NS_ :

BS_:

BU_:
	NEO
	MCU
	GTW
	EPAS
	DI
	ESP
	SBW
	STW
	APP
	DAS
	XXX

VAL_TABLE_ StW_AnglHP_Spd 16383 "SNA" ;
VAL_TABLE_ DI_aebFaultReason 15 "DI_AEB_FAULT_DAS_REQ_DI_UNAVAIL" 14 "DI_AEB_FAULT_ACCEL_REQ_INVALID" 13 "DI_AEB_FAULT_MIN_TIME_BTWN_EVENTS" 12 "DI_AEB_FAULT_ESP_MIA" 11 "DI_AEB_FAULT_ESP_FAULT" 10 "DI_AEB_FAULT_EPB_NOT_PARKED" 9 "DI_AEB_FAULT_ACCEL_OUT_OF_BOUNDS" 8 "DI_AEB_FAULT_PM_REQUEST" 7 "DI_AEB_FAULT_VEL_EST_ABNORMAL" 6 "DI_AEB_FAULT_DAS_SNA" 5 "DI_AEB_FAULT_DAS_CONTROL_MIA" 4 "DI_AEB_FAULT_SPEED_DELTA" 3 "DI_AEB_FAULT_EBR_FAULT" 2 "DI_AEB_FAULT_PM_MIA" 1 "DI_AEB_FAULT_EPB_MIA" 0 "DI_AEB_FAULT_NONE" ;
VAL_TABLE_ DI_aebLockState 3 "AEB_LOCK_STATE_SNA" 2 "AEB_LOCK_STATE_UNUSED" 1 "AEB_LOCK_STATE_UNLOCKED" 0 "AEB_LOCK_STATE_LOCKED" ;
VAL_TABLE_ DI_aebSmState 7 "DI_AEB_STATE_FAULT" 6 "DI_AEB_STATE_EXIT" 5 "DI_AEB_STATE_STANDSTILL" 4 "DI_AEB_STATE_STOPPING" 3 "DI_AEB_STATE_ENABLE" 2 "DI_AEB_STATE_ENABLE_INIT" 1 "DI_AEB_STATE_STANDBY" 0 "DI_AEB_STATE_UNAVAILABLE" ;
VAL_TABLE_ DI_aebState 7 "AEB_CAN_STATE_SNA" 4 "AEB_CAN_STATE_FAULT" 3 "AEB_CAN_STATE_STANDSTILL" 2 "AEB_CAN_STATE_ENABLED" 1 "AEB_CAN_STATE_STANDBY" 0 "AEB_CAN_STATE_UNAVAILABLE" ;
VAL_TABLE_ DI_epbInterfaceReady 1 "EPB_INTERFACE_READY" 0 "EPB_INTERFACE_NOT_READY" ;
VAL_TABLE_ DI_gear 7 "DI_GEAR_SNA" 4 "DI_GEAR_D" 3 "DI_GEAR_N" 2 "DI_GEAR_R" 1 "DI_GEAR_P" 0 "DI_GEAR_INVALID" ;
VAL_TABLE_ DI_gpoReason 8 "DI_GPO_NUMREASONS" 7 "DI_GPO_CAPACITOR_OVERTEMP" 6 "DI_GPO_NOT_ENOUGH_12V" 5 "DI_GPO_NO_BATTERY_POWER" 4 "DI_GPO_AMBIENT_OVERTEMP" 3 "DI_GPO_FLUID_DELTAT" 2 "DI_GPO_STATOR_OVERTEMP" 1 "DI_GPO_HEATSINK_OVERTEMP" 0 "DI_GPO_OUTLET_OVERTEMP" ;
VAL_TABLE_ DI_immobilizerCondition 1 "DI_IMM_CONDITION_LEARNED" 0 "DI_IMM_CONDITION_VIRGIN_SNA" ;
VAL_TABLE_ DI_immobilizerState 7 "DI_IMM_STATE_FAULT" 6 "DI_IMM_STATE_FAULTRETRY" 5 "DI_IMM_STATE_RESET" 4 "DI_IMM_STATE_LEARN" 3 "DI_IMM_STATE_DISARMED" 2 "DI_IMM_STATE_AUTHENTICATING" 1 "DI_IMM_STATE_REQUEST" 0 "DI_IMM_STATE_INIT_SNA" ;
VAL_TABLE_ DI_limpReason 24 "DI_LIMP_NUMREASONS" 23 "DI_LIMP_CAPACITOR_OVERTEMP" 22 "DI_LIMP_GTW_MIA" 21 "DI_LIMP_TRQCMD_VALIDITY_UNKNOWN" 20 "DI_LIMP_DI_MIA" 19 "DI_LIMP_CONFIG_MISMATCH" 18 "DI_LIMP_HEATSINK_TEMP" 17 "DI_LIMP_PMREQUEST" 16 "DI_LIMP_PMHEARTBEAT" 15 "DI_LIMP_TRQ_CROSS_CHECK" 14 "DI_LIMP_EXTERNAL_COMMAND" 13 "DI_LIMP_WRONG_CS_CALIBRATION" 12 "DI_LIMP_STATOR_TEMP" 11 "DI_LIMP_DELTAT_TOO_NEGATIVE" 10 "DI_LIMP_DELTAT_TOO_POSITIVE" 9 "DI_LIMP_AMBIENT_TEMP" 8 "DI_LIMP_OUTLET_TEMP" 7 "DI_LIMP_LOW_FLOW" 6 "DI_LIMP_BMS_MIA" 5 "DI_LIMP_12V_SUPPLY_UNDERVOLTAGE" 4 "DI_LIMP_NO_FLUID" 3 "DI_LIMP_NO_FUNC_HEATSINK_SENSOR" 2 "DI_LIMP_NO_FUNC_STATORT_SENSOR" 1 "DI_LIMP_BUSV_SENSOR_IRRATIONAL" 0 "DI_LIMP_PHASE_IMBALANCE" ;
VAL_TABLE_ DI_mode 2 "DI_MODE_DYNO" 1 "DI_MODE_DRIVE" 0 "DI_MODE_UNDEF" ;
VAL_TABLE_ DI_motorType 14 "DI_MOTOR_F2AE" 13 "DI_MOTOR_F2AD" 12 "DI_MOTOR_F2AC" 11 "DI_MOTOR_F2AB" 10 "DI_MOTOR_F1AC" 9 "DI_MOTOR_SSR1A" 8 "DI_MOTOR_F1A" 7 "DI_MOTOR_M7M6" 6 "DI_MOTOR_M8A" 5 "DI_MOTOR_M7M5" 4 "DI_MOTOR_M7M4" 3 "DI_MOTOR_M7M3" 2 "DI_MOTOR_ROADSTER_SPORT" 1 "DI_MOTOR_ROADSTER_BASE" 0 "DI_MOTOR_SNA" ;
VAL_TABLE_ DI_speedUnits 1 "DI_SPEED_KPH" 0 "DI_SPEED_MPH" ;
VAL_TABLE_ DI_state 4 "DI_STATE_ENABLE" 3 "DI_STATE_FAULT" 2 "DI_STATE_CLEAR_FAULT" 1 "DI_STATE_STANDBY" 0 "DI_STATE_PREAUTH" ;
VAL_TABLE_ DI_velocityEstimatorState 4 "VE_STATE_BACKUP_MOTOR" 3 "VE_STATE_BACKUP_WHEELS_B" 2 "VE_STATE_BACKUP_WHEELS_A" 1 "VE_STATE_WHEELS_NORMAL" 0 "VE_STATE_NOT_INITIALIZED" ;

BO_ 928 EPB_STATUS: 8 XXX
 SG_ EPB_BRAKE : 16|1@1+ (1,0) [0|3] "" XXX

BO_ 1104 SEATBELT_STATUS: 8 XXX
 SG_ DRIVER_SEAT_BELT_ONOFF : 21|1@0+ (1,0) [0|3] "" XXX

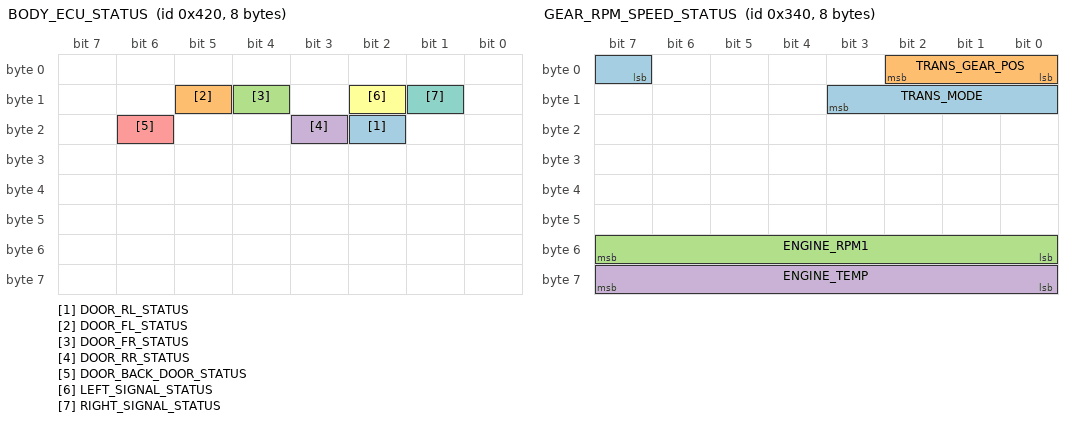
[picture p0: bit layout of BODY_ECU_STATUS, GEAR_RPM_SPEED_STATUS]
BO_ 1056 BODY_ECU_STATUS: 8 XXX
 SG_ DOOR_RL_STATUS : 18|1@0+ (1,0) [0|255] "" XXX
 SG_ DOOR_FL_STATUS : 13|1@0+ (1,0) [0|1] "" XXX
 SG_ DOOR_FR_STATUS : 12|1@0+ (1,0) [0|1] "" XXX
 SG_ DOOR_RR_STATUS : 19|1@0+ (1,0) [0|1] "" XXX
 SG_ DOOR_BACK_DOOR_STATUS : 22|1@0+ (1,0) [0|1] "" XXX
 SG_ LEFT_SIGNAL_STATUS : 10|1@0+ (1,0) [0|1] "" XXX
 SG_ RIGHT_SIGNAL_STATUS : 9|1@0+ (1,0) [0|1] "" XXX

BO_ 832 GEAR_RPM_SPEED_STATUS: 8 XXX
 SG_ TRANS_MODE : 7|5@1+ (1,0) [0|0] "" XXX
 SG_ TRANS_GEAR_POS : 2|3@0+ (1,0) [0|1] "" XXX
 SG_ ENGINE_RPM1 : 55|8@0+ (1,0) [0|255] "" XXX
 SG_ ENGINE_TEMP : 63|8@0+ (1,0) [0|255] "" XXX

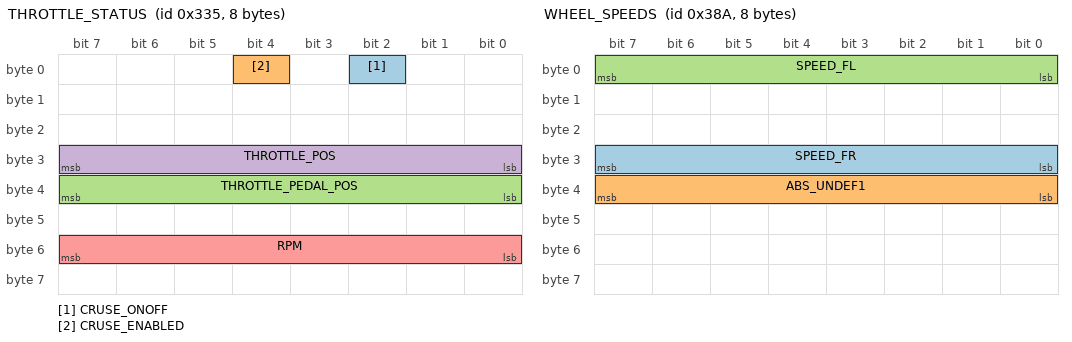
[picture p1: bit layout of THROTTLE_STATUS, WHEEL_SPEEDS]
BO_ 821 THROTTLE_STATUS: 8 XXX
 SG_ CRUSE_ONOFF : 2|1@0+ (1,0) [0|1] "on/off" XXX
 SG_ CRUSE_ENABLED : 4|1@0+ (1,0) [0|1] "" XXX
 SG_ THROTTLE_PEDAL_POS : 32|8@1+ (1,0) [0|255] "" XXX
 SG_ THROTTLE_POS : 24|8@1+ (1,0) [0|255] "" XXX
 SG_ RPM : 48|8@1- (1,0) [0|65535] "" XXX

BO_ 922 STEERING_ANGLE_STATUS: 8 XXX
 SG_ STEER_ANGLE_9000 : 7|16@0- (1,0) [0|65535] "" XXX

BO_ 906 WHEEL_SPEEDS: 8 XXX
 SG_ SPEED_FR : 24|8@1+ (1,0) [0|255] "" XXX
 SG_ ABS_UNDEF1 : 32|8@1+ (1,0) [0|255] "" XXX
 SG_ SPEED_FL : 0|8@1+ (1,0) [0|255] "" XXX

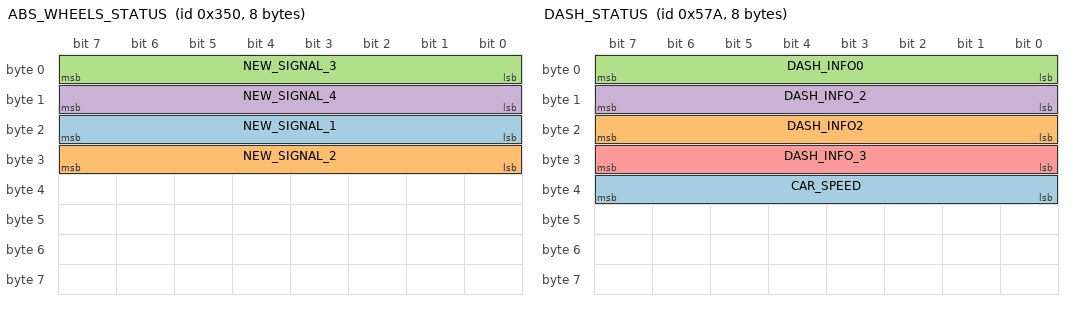
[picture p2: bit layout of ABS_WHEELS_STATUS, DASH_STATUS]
BO_ 848 ABS_WHEELS_STATUS: 8 XXX
 SG_ NEW_SIGNAL_1 : 23|8@0+ (1,0) [0|255] "" XXX
 SG_ NEW_SIGNAL_2 : 31|8@0+ (1,0) [0|255] "" XXX
 SG_ NEW_SIGNAL_3 : 7|8@0+ (1,0) [0|255] "" XXX
 SG_ NEW_SIGNAL_4 : 15|8@0+ (1,0) [0|255] "" XXX

BO_ 1402 DASH_STATUS: 8 XXX
 SG_ CAR_SPEED : 32|8@1+ (1,0) [0|255] "" XXX
 SG_ DASH_INFO2 : 16|8@1+ (1,0) [0|255] "" XXX
 SG_ DASH_INFO0 : 0|8@1+ (1,0) [0|255] "" XXX
 SG_ DASH_INFO_2 : 15|8@0+ (1,0) [0|255] "" XXX
 SG_ DASH_INFO_3 : 31|8@0+ (1,0) [0|255] "" XXX

BO_ 1306 _SPEEDX: 8 XXX
 SG_ DASH_CAR_SPEED : 7|9@0+ (1,0) [0|255] "" XXX

BO_ 1296 undefined: 8 XXX

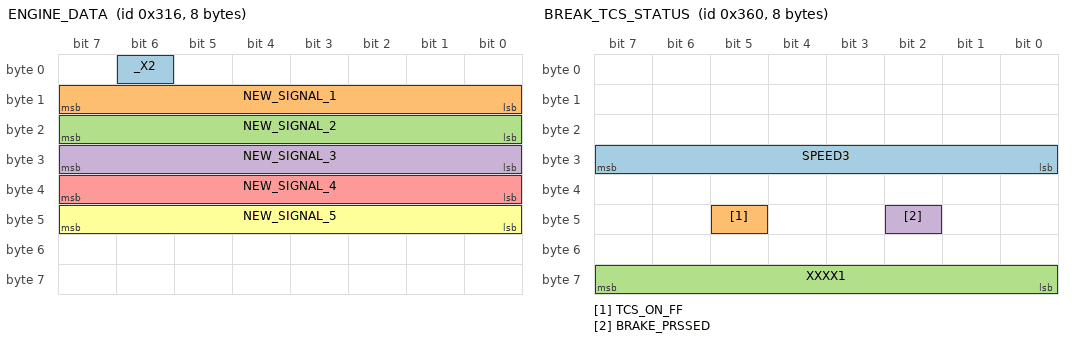
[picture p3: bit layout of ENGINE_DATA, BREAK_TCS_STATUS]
BO_ 790 ENGINE_DATA: 8 XXX
 SG_ _X2 : 6|1@0+ (1,0) [0|1] "" XXX
 SG_ NEW_SIGNAL_1 : 15|8@0+ (1,0) [0|255] "" XXX
 SG_ NEW_SIGNAL_2 : 23|8@0+ (1,0) [0|255] "" XXX
 SG_ NEW_SIGNAL_3 : 31|8@0+ (1,0) [0|255] "" XXX
 SG_ NEW_SIGNAL_4 : 39|8@0+ (1,0) [0|255] "" XXX
 SG_ NEW_SIGNAL_5 : 47|8@0+ (1,0) [0|255] "" XXX

BO_ 1313 undefined_2: 8 XXX

BO_ 1312 __trigger_every_range: 8 XXX
 SG_ __SIGNAL_every_interval : 4|1@0+ (1,0) [0|1] "" XXX

BO_ 896 undefined_3: 8 XXX
 SG_ NEW_SIGNAL_1 : 32|4@1+ (1,0) [0|15] "" XXX

BO_ 809 undefined_4: 8 XXX

BO_ 864 BREAK_TCS_STATUS: 8 XXX
 SG_ SPEED3 : 24|8@1+ (1,0) [0|255] "" XXX
 SG_ TCS_ON_FF : 45|1@0+ (1,0) [0|1] "" XXX
 SG_ XXXX1 : 63|8@0+ (1,0) [0|255] "" XXX
 SG_ BRAKE_PRSSED : 42|1@0+ (1,0) [0|1] "" XXX

BO_ 842 undefined_5: 8 XXX

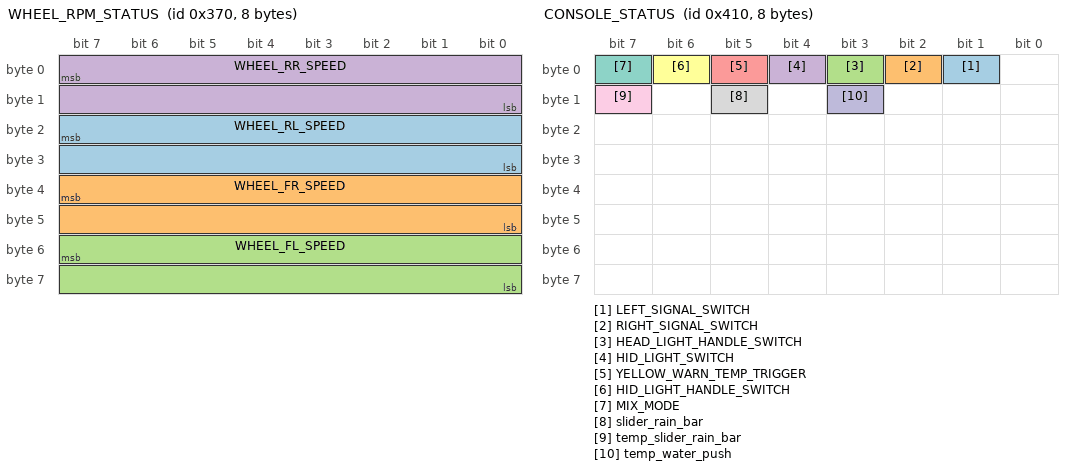
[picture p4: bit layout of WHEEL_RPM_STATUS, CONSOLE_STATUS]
BO_ 880 WHEEL_RPM_STATUS: 8 XXX
 SG_ WHEEL_RL_SPEED : 23|16@0+ (1,0) [0|255] "" XXX
 SG_ WHEEL_FR_SPEED : 39|16@0+ (1,0) [0|255] "" XXX
 SG_ WHEEL_FL_SPEED : 55|16@0+ (1,0) [0|255] "" XXX
 SG_ WHEEL_RR_SPEED : 7|16@0- (1,0) [0|255] "" XXX

BO_ 1040 CONSOLE_STATUS: 8 XXX
 SG_ LEFT_SIGNAL_SWITCH : 1|1@0+ (1,0) [0|1] "" XXX
 SG_ RIGHT_SIGNAL_SWITCH : 2|1@0+ (1,0) [0|1] "" XXX
 SG_ HEAD_LIGHT_HANDLE_SWITCH : 3|1@0+ (1,0) [0|1] "" XXX
 SG_ HID_LIGHT_SWITCH : 4|1@0+ (1,0) [0|1] "" XXX
 SG_ YELLOW_WARN_TEMP_TRIGGER : 5|1@0+ (1,0) [0|1] "" XXX
 SG_ HID_LIGHT_HANDLE_SWITCH : 6|1@0+ (1,0) [0|1] "" XXX
 SG_ MIX_MODE : 7|1@0+ (1,0) [0|1] "" XXX
 SG_ slider_rain_bar : 13|1@0+ (1,0) [0|1] "" XXX
 SG_ temp_slider_rain_bar : 15|1@0+ (1,0) [0|1] "" XXX
 SG_ temp_water_push : 11|1@0+ (1,0) [0|1] "" XXX

BO_ 1120 HAVC_STATUS: 8 XXX
 SG_ HAVC_TEMP : 32|8@1+ (1,0) [0|255] "" XXX

BU_: XXX

CM_ "AUTOGENERATED FILE, DO NOT EDIT";

CM_ "Imported file _stellantis_common.dbc starts here";
CM_ SG_ 258 STEERING_ANGLE_HP "Steering angle high precision";
CM_ SG_ 264 ENGINE_TORQUE "Effective engine torque";
CM_ SG_ 264 EXPECTED_ENGINE_TORQUE "Expected Engine Torque based on target engine speed";
CM_ SG_ 678 LKAS_ICON_COLOR "3 is yellow, 2 is green, 1 is white, 0 is null";
CM_ SG_ 678 LKAS_LANE_LINES "0x01 transparent lines, 0x02 left white, 0x03 right white, 0x04 left yellow with car on top, 0x05 left yellow with car on top, 0x06 both white, 0x07 left yellow, 0x08 left yellow right white, 0x09 right yellow, 0x0a right yellow left white, 0x0b left yellow with car on top right white, 0x0c right yellow with car on top left white, (0x00, 0x0d, 0x0e, 0x0f) null";
CM_ SG_ 678 LKAS_ALERTS "(0x01, 0x02) lane sense off, (0x03, 0x04, 0x06) place hands on steering wheel, 0x07 lane departure detected + place hands on steering wheel, (0x08, 0x09) lane sense unavailable + clean front windshield, 0x0b lane sense and auto high beam unavailable + clean front windshield, 0x0c lane sense unavailable + service required, (0x00, 0x05, 0x0a, 0x0d, 0x0e, 0x0f) null";

CM_ "chrysler_pacifica_2017_hybrid.dbc starts here";

CM_ SG_ 653 BRAKE_PRESSURE "max seems to be 148";
CM_ SG_ 746 PRNDL "5=L, 4=D, 3=N, 2=R, 1=P";
CM_ SG_ 320 BRAKE_PRESSED_2 "Value is 5 when brake is pressed by human, 1 when ACC brake";
CM_ SG_ 320 BRAKE_PRESSED_ACC "set when ACC brakes";
CM_ SG_ 792 TURN_SIGNALS "1=Left, 2=Right";
CM_ SG_ 264 ACCEL_PEDAL "not in ACC so seems to be actual pedal. Use for gasPressed";
CM_ SG_ 544 LKAS_STATE "2 when autopark has control, 8 when is actuatable by lkas, 4 when there is a fault";
CM_ SG_ 658 LKAS_STEERING_TORQUE "Most sent by stock system is 1024+-230. + is left. typically changes by 2 or 3 each 0.01s";
CM_ SG_ 678 LKAS_ICON_COLOR "3 is yellow, 2 is green, 1 is white, 0 is null";
CM_ SG_ 678 LKAS_LANE_LINES "0x01 transparent lines, 0x02 left white, 0x03 right white, 0x04 left yellow with car on top, 0x05 left yellow with car on top, 0x06 both white, 0x07 left yellow, 0x08 left yellow right white, 0x09 right yellow, 0x0a right yellow left white, 0x0b left yellow with car on top right white, 0x0c right yellow with car on top left white, (0x00, 0x0d, 0x0e, 0x0f) null";
CM_ SG_ 678 LKAS_ALERTS "(0x01, 0x02) lane sense off, (0x03, 0x04, 0x06) place hands on steering wheel, 0x07 lane departure detected + place hands on steering wheel, (0x08, 0x09) lane sense unavailable + clean front windshield, 0x0b lane sense and auto high beam unavailable + clean front windshield, 0x0c lane sense unavailable + service required, (0x00, 0x05, 0x0a, 0x0d, 0x0e, 0x0f) null";
CM_ SG_ 705 AUTO_PARK_TOGGLE_1 "set briefly when turning on or off self-parking";
CM_ SG_ 671 AUTO_PARK_CMD "Request Appears to be in NM";
CM_ SG_ 671 AUTO_PARK_STATUS "1 = IDLE / NO REQUEST 9 = START REQUEST 10 = REQUEST MODE 11 = REQUEST MODE";
CM_ SG_ 826 AUTO_PARK_GEAR_1 "Reverse=0, Forward=f";
CM_ SG_ 826 AUTO_PARK_GEAR_2 "Reverse=0, Forward=f";
CM_ SG_ 826 AUTO_PARK_GEAR_3 "Reverse=0, Forward=f";
CM_ SG_ 332 STEER_ANGLE_2 "slightly lags the other steer_angle signal. also more noisy.";
CM_ SG_ 608 PARKSENSE_DISABLED "set if parksense is disabled";
CM_ SG_ 729 LKAS_STATUS_OK "Set to 0x0820 when LKAS system is plugged in.";
CM_ SG_ 825 BEEP_339 "sent every 0.5s. 0050 is no beep. To beep send 4355 or 4155. Used by ParkSense warning.";
CM_ SG_ 270 ELECTRIC_MOTOR "0x7fff indicates electric motor not in use";
CM_ SG_ 291 ENERGY_GAIN_LOSS "unsure what this actually is";
CM_ SG_ 291 ENERGY_SMOOTHER_CURVE "unsure what it is, but smoother";
CM_ SG_ 308 ACCEL_134 "only set when human presses accel pedal";
CM_ SG_ 532 NOISY_SLOWLY_DECREASING "perhaps battery but do not know";
CM_ SG_ 816 TRACTION_OFF "set when traction off button is enabled";
CM_ SG_ 816 TOGGLE_PARKSENSE "sending 3000071ec0ff9000 enables or disables parksense";
CM_ SG_ 324 SPEED_2 "signal is approx half other speeds";
CM_ SG_ 501 ACC_SPEED_CONFIG_KPH "speed configured for ACC";
CM_ SG_ 501 ACC_SPEED_CONFIG_MPH "speed configured for ACC";
CM_ SG_ 501 CRUISE_STATE "may just be an icon, but seems to indicate different cruise modes: ACC and Non-ACC and engaged state for both.";
CM_ SG_ 625 SPEED "zero on non-acc drives";

VAL_ 328 Gear 0 "N" 1 "D" 2 "D" 3 "D" 4 "D" 5 "D" 6 "D" 14 "R" 15 "P";
